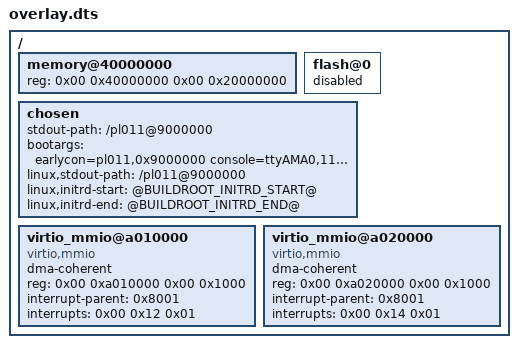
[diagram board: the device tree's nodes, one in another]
/*
 * Copyright 2024, UNSW
 *
 * SPDX-License-Identifier: BSD-2-Clause
 *
 * Buildroot guest overlay. vmm.mk fills @BUILDROOT_INITRD_*@ from the
 * packaged initrd size. RAM / initrd IPA must match linux_vmm.c
 * (LINUX_GUEST_RAM_VADDR / GUEST_INIT_RAM_DISK_VADDR / GUEST_RAM_SIZE).
 *
 * Guest I/O is emulated virtio-mmio only:
 *   net  0xa010000  SPI 18 → INTID 50
 *   blk  0xa020000  SPI 20 → INTID 52
 * QEMU virtio-net/blk (0xa000000 / 0xa000200) are not in this tree.
 */
/ {
    /* Need to specify how much RAM the guest will have */
    memory@40000000 {
        device_type = "memory";
        reg = <0x00 0x40000000 0x00 0x20000000>;
    };

    flash@0 {
        status = "disabled";
    };

    chosen {
        stdout-path = "/pl011@9000000";
        bootargs = "earlycon=pl011,0x9000000 console=ttyAMA0,115200n8 earlyprintk=serial debug loglevel=8 ip=dhcp";
        linux,stdout-path = "/pl011@9000000";
        linux,initrd-start = <@BUILDROOT_INITRD_START@>;
        linux,initrd-end = <@BUILDROOT_INITRD_END@>;
    };

    /* agentOS emulated virtio-net (not QEMU). SPI 18 → INTID 50. */
    virtio_mmio@a010000 {
        compatible = "virtio,mmio";
        dma-coherent;
        reg = <0x00 0xa010000 0x00 0x1000>;
        interrupt-parent = <0x8001>;
        interrupts = <0x00 0x12 0x01>;
    };

    /* agentOS emulated virtio-blk (sDDF RAM pump, not QEMU). SPI 20 → INTID 52. */
    virtio_mmio@a020000 {
        compatible = "virtio,mmio";
        dma-coherent;
        reg = <0x00 0xa020000 0x00 0x1000>;
        interrupt-parent = <0x8001>;
        interrupts = <0x00 0x14 0x01>;
    };
};
